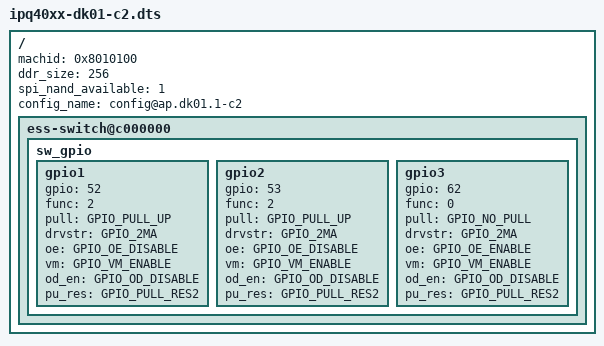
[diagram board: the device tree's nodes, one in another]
/*
 * Copyright (c) 2016, The Linux Foundation. All rights reserved.
 *
 * This program is free software; you can redistribute it and/or modify
 * it under the terms of the GNU General Public License version 2 and
 * only version 2 as published by the Free Software Foundation.
 *
 * This program is distributed in the hope that it will be useful,
 * but WITHOUT ANY WARRANTY; without even the implied warranty of
 * MERCHANTABILITY or FITNESS FOR A PARTICULAR PURPOSE.  See the
 * GNU General Public License for more details.
 */

/dts-v1/;
#include "ipq40xx-dk01.dtsi"
/ {
	machid = <0x8010100>;
	ddr_size = <256>;
	spi_nand_available = <1>;
	config_name = "config@ap.dk01.1-c2";

	ess-switch@c000000{
		sw_gpio {
			gpio1 {
				gpio = <52>;
				func = <2>;
				pull = <GPIO_PULL_UP>;
				drvstr = <GPIO_2MA>;
				oe = <GPIO_OE_DISABLE>;
				vm = <GPIO_VM_ENABLE>;
				od_en = <GPIO_OD_DISABLE>;
				pu_res = <GPIO_PULL_RES2>;
			};

			gpio2 {
				gpio = <53>;
				func = <2>;
				pull = <GPIO_PULL_UP>;
				drvstr = <GPIO_2MA>;
				oe = <GPIO_OE_DISABLE>;
				vm = <GPIO_VM_ENABLE>;
				od_en = <GPIO_OD_DISABLE>;
				pu_res = <GPIO_PULL_RES2>;
			};

			gpio3 {
				gpio = <62>;
				func = <0>;
				pull = <GPIO_NO_PULL>;
				drvstr = <GPIO_2MA>;
				oe = <GPIO_OE_ENABLE>;
				vm = <GPIO_VM_ENABLE>;
				od_en = <GPIO_OD_DISABLE>;
				pu_res = <GPIO_PULL_RES2>;
			};
		};
	};

};
